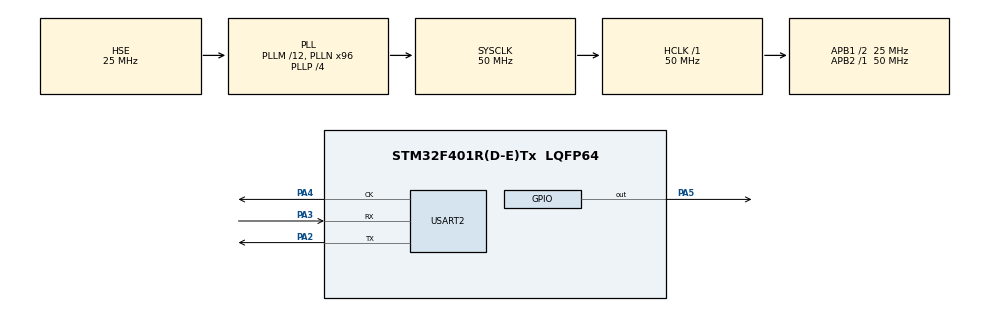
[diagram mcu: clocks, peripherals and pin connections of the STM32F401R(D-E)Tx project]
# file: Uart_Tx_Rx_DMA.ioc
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Dma.Request0=USART2_TX
Dma.Request1=USART2_RX
Dma.USART2_RX.1.Direction=DMA_PERIPH_TO_MEMORY
Dma.USART2_RX.1.FIFOMode=DMA_FIFOMODE_DISABLE
Dma.USART2_RX.1.Instance=DMA1_Stream5
Dma.USART2_RX.1.MemDataAlignment=DMA_MDATAALIGN_WORD
Dma.USART2_RX.1.MemInc=DMA_MINC_ENABLE
Dma.USART2_RX.1.Mode=DMA_CIRCULAR
Dma.USART2_RX.1.PeriphDataAlignment=DMA_PDATAALIGN_WORD
Dma.USART2_RX.1.PeriphInc=DMA_PINC_DISABLE
Dma.USART2_RX.1.Priority=DMA_PRIORITY_LOW
Dma.USART2_TX.0.Direction=DMA_MEMORY_TO_PERIPH
Dma.USART2_TX.0.FIFOMode=DMA_FIFOMODE_DISABLE
Dma.USART2_TX.0.Instance=DMA1_Stream6
Dma.USART2_TX.0.MemDataAlignment=DMA_MDATAALIGN_WORD
Dma.USART2_TX.0.MemInc=DMA_MINC_ENABLE
Dma.USART2_TX.0.Mode=DMA_NORMAL
Dma.USART2_TX.0.PeriphDataAlignment=DMA_PDATAALIGN_WORD
Dma.USART2_TX.0.PeriphInc=DMA_PINC_DISABLE
Dma.USART2_TX.0.Priority=DMA_PRIORITY_LOW
Mcu.Family=STM32F4
Mcu.Name=STM32F401R(D-E)Tx
Mcu.Package=LQFP64
NVIC.DMA1_Stream5_IRQn=true\:0\:0\:false\:false\:true\:false\:true
NVIC.DMA1_Stream6_IRQn=true\:0\:0\:false\:false\:true\:false\:true
NVIC.PriorityGroup=NVIC_PRIORITYGROUP_4
PA13.Mode=Serial_Wire
PA13.Signal=SYS_JTMS-SWDIO
PA14.Mode=Serial_Wire
PA14.Signal=SYS_JTCK-SWCLK
PA2.Mode=Synchronous
PA2.Signal=USART2_TX
PA3.Mode=Synchronous
PA3.Signal=USART2_RX
PA4.Mode=Synchronous
PA4.Signal=USART2_CK
PA5.Signal=GPIO_Output
PH0\ -\ OSC_IN.Mode=HSE-External-Oscillator
PH0\ -\ OSC_IN.Signal=RCC_OSC_IN
PH1\ -\ OSC_OUT.Mode=HSE-External-Oscillator
PH1\ -\ OSC_OUT.Signal=RCC_OSC_OUT
ProjectManager.HeapSize=0x200
ProjectManager.StackSize=0x400
ProjectManager.TargetToolchain=STM32CubeIDE
RCC.48MHZClocksFreq_Value=50000000
RCC.AHBFreq_Value=50000000
RCC.APB1CLKDivider=RCC_HCLK_DIV2
RCC.APB1Freq_Value=25000000
RCC.APB1TimFreq_Value=50000000
RCC.APB2Freq_Value=50000000
RCC.APB2TimFreq_Value=50000000
RCC.CortexFreq_Value=50000000
RCC.HCLKFreq_Value=50000000
RCC.HSE_VALUE=25000000
RCC.HSI_VALUE=16000000
RCC.LSE_VALUE=32768
RCC.PLLM=12
RCC.PLLN=96
RCC.PLLP=RCC_PLLP_DIV4
RCC.PLLSourceVirtual=RCC_PLLSOURCE_HSE
RCC.SYSCLKFreq_VALUE=50000000
RCC.SYSCLKSource=RCC_SYSCLKSOURCE_PLLCLK
RCC.VCOOutputFreq_Value=200000000
USART2.VirtualMode=VM_SYNC
board=custom

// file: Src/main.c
/* USER CODE BEGIN Header */
/**
  ******************************************************************************
  * @file           : main.c
  * @brief          : Main program body
  ******************************************************************************
  * @attention
  *
  * <h2><center>&copy; Copyright (c) 2021 STMicroelectronics.
  * All rights reserved.</center></h2>
  *
  * This software component is licensed by ST under BSD 3-Clause license,
  * the "License"; You may not use this file except in compliance with the
  * License. You may obtain a copy of the License at:
  *                        opensource.org/licenses/BSD-3-Clause
  *
  ******************************************************************************
  */
/* USER CODE END Header */
#include "main.h"

USART_HandleTypeDef husart2;
DMA_HandleTypeDef hdma_usart2_tx;
DMA_HandleTypeDef hdma_usart2_rx;

void SystemClock_Config(void);
static void MX_GPIO_Init(void);
static void MX_DMA_Init(void);
static void MX_USART2_Init(void);

/* USER CODE BEGIN 0 */

char data[2000];

 uint8_t count =0;

void HAL_USART_TxHalfCpltCallback(USART_HandleTypeDef *husart)
{
  for (int i=0; i<1000; i++)
    {
	data[i] = 'x';
    }
}

void HAL_USART_TxCpltCallback(USART_HandleTypeDef *husart){

	  for (int i=1000; i<2000; i++)
	    {
		data[i] = 'y';
	    }
}

/* USER CODE END 0 */

int main(void)
{

  /* MCU Configuration--------------------------------------------------------*/

  /* Reset of all peripherals, Initializes the Flash interface and the Systick. */
  HAL_Init();

  /* Configure the system clock */
  SystemClock_Config();

  /* Initialize all configured peripherals */
  MX_GPIO_Init();
  MX_DMA_Init();
  MX_USART2_Init();
  /* USER CODE BEGIN 2 */

	for (int i=0; i<1000; i++)
	  {
		data[i] = 'z';
	  }

  HAL_USART_Transmit_DMA(&husart2, &data, count);

  while (1)
  {

  }

}

//void HAL_USART_TxHalfCpltCallback(USART_HandleTypeDef *husart)
//{
//    for (int i=1000; i<2000; i++)
 //   {
//	data[i] = 'y';
//    }
//}

void SystemClock_Config(void)
{
  RCC_OscInitTypeDef RCC_OscInitStruct = {0};
  RCC_ClkInitTypeDef RCC_ClkInitStruct = {0};

  /** Configure the main internal regulator output voltage
  */
  __HAL_RCC_PWR_CLK_ENABLE();
  __HAL_PWR_VOLTAGESCALING_CONFIG(PWR_REGULATOR_VOLTAGE_SCALE2);
  /** Initializes the RCC Oscillators according to the specified parameters
  * in the RCC_OscInitTypeDef structure.
  */
  RCC_OscInitStruct.OscillatorType = RCC_OSCILLATORTYPE_HSE;
  RCC_OscInitStruct.HSEState = RCC_HSE_ON;
  RCC_OscInitStruct.PLL.PLLState = RCC_PLL_ON;
  RCC_OscInitStruct.PLL.PLLSource = RCC_PLLSOURCE_HSE;
  RCC_OscInitStruct.PLL.PLLM = 12;
  RCC_OscInitStruct.PLL.PLLN = 96;
  RCC_OscInitStruct.PLL.PLLP = RCC_PLLP_DIV4;
  RCC_OscInitStruct.PLL.PLLQ = 4;
  if (HAL_RCC_OscConfig(&RCC_OscInitStruct) != HAL_OK)
  {
    Error_Handler();
  }
  /** Initializes the CPU, AHB and APB buses clocks
  */
  RCC_ClkInitStruct.ClockType = RCC_CLOCKTYPE_HCLK|RCC_CLOCKTYPE_SYSCLK
                              |RCC_CLOCKTYPE_PCLK1|RCC_CLOCKTYPE_PCLK2;
  RCC_ClkInitStruct.SYSCLKSource = RCC_SYSCLKSOURCE_PLLCLK;
  RCC_ClkInitStruct.AHBCLKDivider = RCC_SYSCLK_DIV1;
  RCC_ClkInitStruct.APB1CLKDivider = RCC_HCLK_DIV2;
  RCC_ClkInitStruct.APB2CLKDivider = RCC_HCLK_DIV1;

  if (HAL_RCC_ClockConfig(&RCC_ClkInitStruct, FLASH_LATENCY_1) != HAL_OK)
  {
    Error_Handler();
  }
}

static void MX_USART2_Init(void)
{

  husart2.Instance = USART2;
  husart2.Init.BaudRate = 115200;
  husart2.Init.WordLength = USART_WORDLENGTH_8B;
  husart2.Init.StopBits = USART_STOPBITS_1;
  husart2.Init.Parity = USART_PARITY_NONE;
  husart2.Init.Mode = USART_MODE_TX_RX;
  husart2.Init.CLKPolarity = USART_POLARITY_LOW;
  husart2.Init.CLKPhase = USART_PHASE_1EDGE;
  husart2.Init.CLKLastBit = USART_LASTBIT_DISABLE;
  if (HAL_USART_Init(&husart2) != HAL_OK)
  {
    Error_Handler();
  }

}

static void MX_DMA_Init(void)
{

  /* DMA controller clock enable */
  __HAL_RCC_DMA1_CLK_ENABLE();

  /* DMA interrupt init */
  /* DMA1_Stream5_IRQn interrupt configuration */
  HAL_NVIC_SetPriority(DMA1_Stream5_IRQn, 0, 0);
  HAL_NVIC_EnableIRQ(DMA1_Stream5_IRQn);
  /* DMA1_Stream6_IRQn interrupt configuration */
  HAL_NVIC_SetPriority(DMA1_Stream6_IRQn, 0, 0);
  HAL_NVIC_EnableIRQ(DMA1_Stream6_IRQn);

}

static void MX_GPIO_Init(void)
{
  GPIO_InitTypeDef GPIO_InitStruct = {0};

  /* GPIO Ports Clock Enable */
  __HAL_RCC_GPIOH_CLK_ENABLE();
  __HAL_RCC_GPIOA_CLK_ENABLE();

  /*Configure GPIO pin Output Level */
  HAL_GPIO_WritePin(GPIOA, GPIO_PIN_5, GPIO_PIN_RESET);

  /*Configure GPIO pin : PA5 */
  GPIO_InitStruct.Pin = GPIO_PIN_5;
  GPIO_InitStruct.Mode = GPIO_MODE_OUTPUT_PP;
  GPIO_InitStruct.Pull = GPIO_NOPULL;
  GPIO_InitStruct.Speed = GPIO_SPEED_FREQ_LOW;
  HAL_GPIO_Init(GPIOA, &GPIO_InitStruct);

}

void Error_Handler(void)
{
  __disable_irq();
  while (1)
  {
  }
}

/************************ (C) COPYRIGHT STMicroelectronics *****END OF FILE****/
